# STM32H7R register map
File version: 1.3
CPU: CM7 r0p1, little endian, MPU, FPU, 4 interrupt priority bits
Registers are 32-bit, read-write, reset 0x0 unless marked. A register's access mark holds for its fields unless they carry their own. Offsets are from the block's base; [hi:lo] are bit positions; <NAME> marks a mode.

## ADF — Audio digital filter
Base 0x4002F000
0x00 GCR — ADF global control register
  [0] TRGO — Trigger output control This bit is set by software and reset by hardware. It is used to start the acquisition of several filters synchronously. It is also used to synchronize several ADF together by controlling the adf_trgo signal.
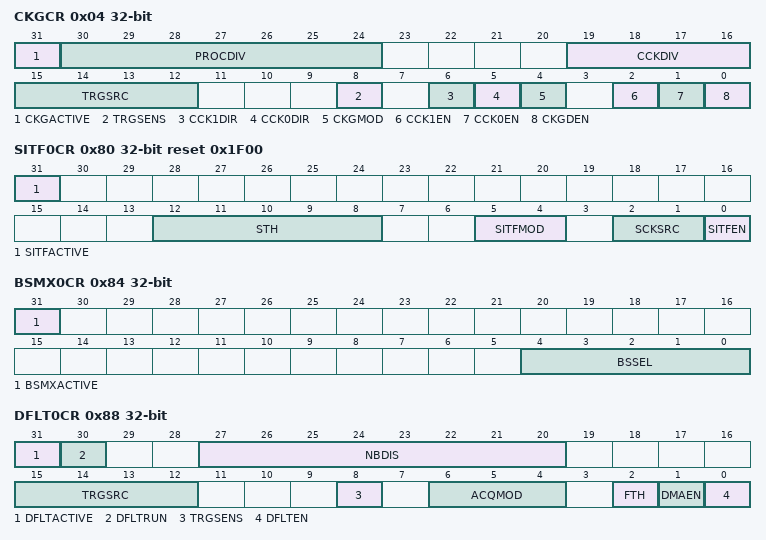
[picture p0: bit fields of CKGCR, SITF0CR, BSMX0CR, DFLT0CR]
0x04 CKGCR access per field — ADF clock generator control register
  [31] CKGACTIVE ro — Clock generator active flag This bit is set and cleared by hardware. Ii is used by the application to check if the clock generator is effectively enabled (active) or not. The protected fields of this function can only be updated when CKGACTIVE = 0 (see Section 46.4.13: Register protection for details). The delay between a transition on CKGDEN and a transition on CKGACTIVE is two periods of AHB clock and two 2 periods of adf_proc_ck.
  [30:24] PROCDIV rw — Divider to control the serial interface clock this field is set and reset by software. It is used to adjust the frequency of the clock provided to the SITF. This field must not be changed if the filter is enabled (DFTEN = 1). ... Note: This field can be write-protected (see Section 46.4.13: Register protection for details).
  [19:16] CCKDIV rw — Divider to control the ADF_CCK clock This field is set and reset by software. It is used to adjust the frequency of the ADF_CCK clock. The input clock of this divider is the clock provided to the SITF. More globally, the frequency of the ADF_CCK is given by the following formula: This field must not be changed if the filter is enabled (DFTEN = 1). ... Note: This field can be write-protected (see Section 46.4.13: Register protection for details).
  [15:12] TRGSRC rw — Digital filter trigger signal selection This field is set and cleared by software. It is used to select which external signals trigger the corresponding filter. This field is not significant if the CKGMOD = 0. 000x: TRGO selected others: reserved Note: This field can be write-protected (see Section 46.4.13: Register protection for details).
  [8] TRGSENS rw — CKGEN trigger sensitivity selection This bit is set and cleared by software. It is used to select the trigger sensitivity of the trigger signals. This bit is not significant if the CKGMOD = 0. Note: When the trigger source is TRGO, the sensitivity is forced to falling edge, thus TRGSENS value is not taken into account. This bit can be write-protected (see Section 46.4.13: Register protection for details).
  [6] CCK1DIR rw — ADF_CCK1 direction This bit is set and reset by software. It is used to control the direction of the ADF_CCK1 pin. Note: This bit can be write-protected (see Section 46.4.13: Register protection for details).
  [5] CCK0DIR rw — ADF_CCK0 direction This bit is set and reset by software. It is used to control the direction of the ADF_CCK0 pin. Note: This bit can be write-protected (see Section 46.4.13: Register protection for details).
  [4] CKGMOD rw — Clock generator mode This bit is set and reset by software. It is used to define the way the clock generator is enabled. This bit must not be changed if the filter is enabled (DFTEN = 1). Note: This bit can be write-protected (see Section 46.4.13: Register protection for details).
  [2] CCK1EN rw — ADF_CCK1 clock enable This bit is set and reset by software. It is used to control the generation of the bitstream clock on the ADF_CCK1 pin.
  [1] CCK0EN rw — ADF_CCK0 clock enable This bit is set and reset by software. It is used to control the generation of the bitstream clock on the ADF_CCK0 pin.
  [0] CKGDEN rw — CKGEN dividers enable This bit is set and reset by software. It is used to enable/disable the clock dividers of the CKGEN: PROCDIV and CCKDIV.
0x80 SITF0CR access per field reset 0x1F00 — ADF serial interface control register 0
  [31] SITFACTIVE ro — Serial interface active flag This bit is set and cleared by hardware. It is used by the application to check if the serial interface is effectively enabled (active) or not. The protected fields of this function can only be updated when SITFACTIVE is set to 0 (see Section 46.4.13: Register protection for details). The delay between a transition on SITFEN and a transition on SITFACTIVE is two periods of AHB clock and two periods of adf_proc_ck.
  [12:8] STH rw — Manchester symbol threshold/SPI threshold This field is set and cleared by software. It is used for Manchester mode to define the expected symbol threshold levels (seer to Manchester mode for details on computation). In addition this field is used to define the timeout value for the clock absence detection in Normal SPI mode. STH[4:0] values lower than four are invalid. Note: This field can be write-protected (see Section 46.4.13: Register protection for details).
  [5:4] SITFMOD rw — Serial interface type This field is set and cleared by software. It is used to define the serial interface type. Note: This field can be write-protected (see Section 46.4.13: Register protection for details).
  [2:1] SCKSRC rw — Serial clock source This field is set and cleared by software. It is used to select the clock source of the serial interface. others: reserved Note: This field can be write-protected (see Section 46.4.13: Register protection for details).
  [0] SITFEN rw — Serial interface enable This bit is set and cleared by software. It is used to enable/disable the serial interface.
0x84 BSMX0CR access per field — ADF bitstream matrix control register 0
  [31] BSMXACTIVE ro — BSMX active flag This bit is set and cleared by hardware. It is used by the application to check if the BSMX is effectively enabled (active) or not. BSSEL[4:0] can only be updated when BSMXACTIVE is set to 0. This BSMXACTIVE flag cannot go to 0 if DFLT0 is enabled.
  [4:0] BSSEL rw — Bitstream selection This field is set and cleared by software. It is used to select the bitstream to be processed for DFLT0. others: reserved Note: This field can be write-protected (see Section 46.4.13: Register protection for details).
0x88 DFLT0CR access per field — ADF digital filter control register 0
  [31] DFLTACTIVE ro — DFLT0 active flag This bit is set and cleared by hardware. It indicates if DFLT0 is active: can be running or waiting for events.
  [30] DFLTRUN ro — DFLT0 run status flag This bit is set and cleared by hardware. It indicates if DFLT0 is running or not.
  [27:20] NBDIS rw — Number of samples to be discarded This field is set and cleared by software. It is used to define the number of samples to be discarded every time DFLT0 is re-started. ... Note: This field can be write-protected (see Section 46.4.13: Register protection for details).
  [15:12] TRGSRC rw — DFLT0 trigger signal selection This field is set and cleared by software. It is used to select which external signals trigger DFLT0. others: Reserved Note: This field can be write-protected (see Section 46.4.13: Register protection for details).
  [8] TRGSENS rw — DFLT0 trigger sensitivity selection This field is set and cleared by software. It is used to select the trigger sensitivity of the external signals When the trigger source is TRGO, TRGSENS value is not taken into account. When TRGO is selected, the sensitivity is forced to falling edge. Note: This bit can be write-protected (see Section 46.4.13: Register protection for details).
  [6:4] ACQMOD rw — DFLT0 trigger mode This field is set and cleared by software. It is used to select the filter trigger mode. others: same as 000 Note: This field can be write-protected (see Section 46.4.13: Register protection for details)..
  [2] FTH rw — RXFIFO threshold selection This bit is set and cleared by software. It is used to select the RXFIFO threshold. Note: This bit can be write-protected (see Section 46.4.13: Register protection for details).
  [1] DMAEN rw — DMA requests enable This bit is set and cleared by software. It is used to control the generation of DMA request to transfer the processed samples into the memory. Note: This bit can be write-protected (see Section 46.4.13: Register protection for details).
  [0] DFLTEN wo — DFLT0 enable This bit is set and cleared by software. It is used to control the start of acquisition of the DFLT0 path. This bit behavior depends on ACQMOD[2:0] and external events. The serial or parallel interface delivering the samples must be enabled as well.
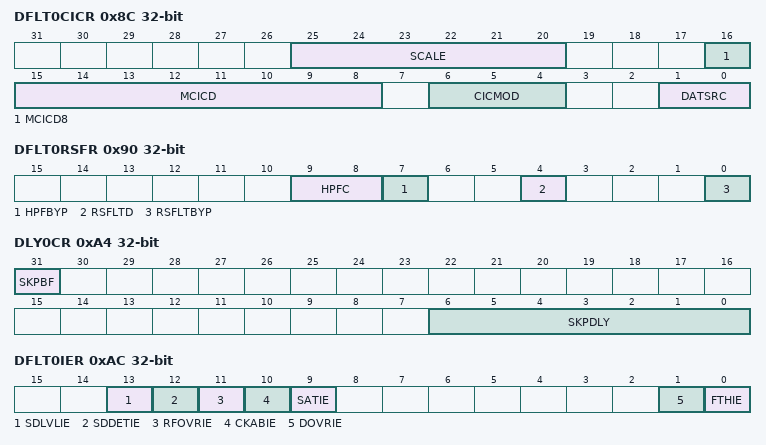
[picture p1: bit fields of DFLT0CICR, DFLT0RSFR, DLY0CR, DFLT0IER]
0x8C DFLT0CICR — ADF digital filer configuration register 0
  [25:20] SCALE — Scaling factor selection This field is set and cleared by software. It is used to select the gain to be applied at CIC output (see Table 419 for details). If the application attempts to write a new gain value while the previous one is not yet applied, this new gain value is ignored. Reading back this field informs the application on the current gain value. ... ... others: Reserved
  [16] MCICD8 — CIC decimation ratio selection This field is set and cleared by software.It is used to select the CIC decimation ratio. A decimation ratio smaller than two is not allowed. The decimation ratio is given by (CICDEC+1). ... Note: This field can be write-protected (see Section 46.4.13: Register protection for details).
  [15:8] MCICD — CIC decimation ratio selection This field is set and cleared by software.It is used to select the CIC decimation ratio. A decimation ratio smaller than two is not allowed. The decimation ratio is given by (CICDEC+1). ... Note: This field can be write-protected (see Section 46.4.13: Register protection for details).
  [6:4] CICMOD — Select the CIC order This field is set and cleared by software. It is used to select the order of the MCIC. others: reserved Note: This field can be write-protected (see Section 46.4.13: Register protection for details).
  [1:0] DATSRC — Source data for the digital filter This field is set and cleared by software. 0x: Stream coming from the BSMX selected Note: This field can be write-protected (see Section 46.4.13: Register protection for details).
0x90 DFLT0RSFR — ADF reshape filter configuration register 0
  [9:8] HPFC — High-pass filter cut-off frequency This field is set and cleared by software. it is used to select the cut-off frequency of the high-pass filter. F<sub>PCM</sub> represents the sampling frequency at HPF input. Note: This field can be write-protected (see Section 46.4.13: Register protection for details).
  [7] HPFBYP — High-pass filter bypass This bit is set and cleared by software. It is used to bypass the high-pass filter. Note: This bit can be write-protected (see Section 46.4.13: Register protection for details).
  [4] RSFLTD — Reshaper filter decimation ratio This bit is set and cleared by software. It is used to select the decimation ratio for the reshape filter Note: This bit can be write-protected (see Section 46.4.13: Register protection for details).
  [0] RSFLTBYP — Reshaper filter bypass This bit is set and cleared by software. It is used to bypass the reshape filter and its decimation block. Note: This bit can be write-protected (see Section 46.4.13: Register protection for details).
0xA4 DLY0CR access per field — ADF delay control register 0
  [31] SKPBF ro — Skip busy flag This bit is set and cleared by hardware. It is used to control if the delay sequence is completed.
  [6:0] SKPDLY rw — Delay to apply to a bitstream This field is set and cleared by software. It defines the number of input samples that are skipped. Skipping is applied immediately after writing to this field, if SKPBF = 0 and DFLTEN = 1. If SKPBF = 1, the value written into the register is ignored by the delay state machine. ...
0xAC DFLT0IER — ADF DFLT0 interrupt enable register
  [13] SDLVLIE — SAD sound-level value ready enable This bit is set and cleared by software.
  [12] SDDETIE — Sound activity detection interrupt enable This bit is set and cleared by software.
  [11] RFOVRIE — Reshape filter overrun interrupt enable This bit is set and cleared by software.
  [10] CKABIE — Clock absence detection interrupt enable This bit is set and cleared by software.
  [9] SATIE — Saturation detection interrupt enable This bit is set and cleared by software.
  [1] DOVRIE — Data overflow interrupt enable This bit is set and cleared by software.
  [0] FTHIE — RXFIFO threshold interrupt enable This bit is set and cleared by software.
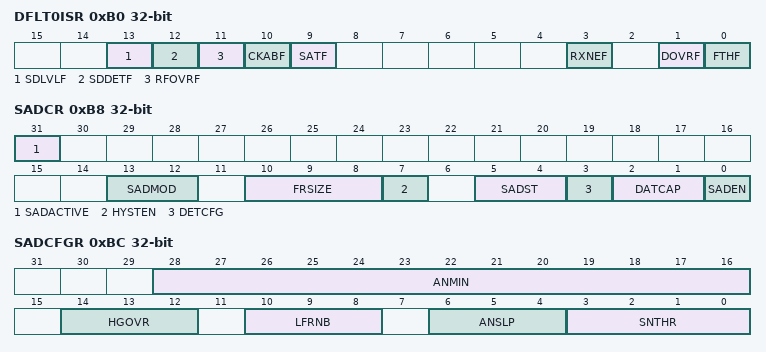
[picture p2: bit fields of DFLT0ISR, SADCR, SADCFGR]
0xB0 DFLT0ISR access per field — ADF DFLT0 interrupt status register 0
  [13] SDLVLF rw — Sound level value ready flag This bit is set by hardware and cleared by software by writing this bit to 1.
  [12] SDDETF rw — Sound activity detection flag This bit is set by hardware and cleared by software by writing this bit to 1.
  [11] RFOVRF rw — Reshape filter overrun detection flag This bit is set by hardware and cleared by software by writing this bit to 1.
  [10] CKABF rw — Clock absence detection flag This bit is set by hardware and cleared by software by writing this bit to 1.
  [9] SATF rw — Saturation detection flag This bit is set by hardware and cleared by software by writing this bit to 1.
  [3] RXNEF ro — RXFIFO not empty flag This bit is set and cleared by hardware according to the RXFIFO level.
  [1] DOVRF rw — Data overflow flag This bit is set by hardware and cleared by software by writing this bit to 1.
  [0] FTHF ro — RXFIFO threshold flag This bit is set by hardware, and cleared by the hardware when the RXFIFO level is lower than the threshold.
0xB8 SADCR access per field — ADF SAD control register
  [31] SADACTIVE ro — SAD Active flag This bit is set and cleared by hardware. It is used to check if the SAD is effectively enabled (active) or not. The protected fields and registers of this function can only be updated when the SADACTIVE is set to 0 (see Section 46.4.13: Register protection for details). The delay between a transition on SADEN and a transition on SADACTIVE is two periods of AHB clock and two periods of adf_proc_ck.
  [13:12] SADMOD rw — SAD working mode This field is set and cleared by software. It is used to define the way the SAD works. The SAD triggers when the sound level (SDLVL) is bigger than the defined threshold. In this mode, the SAD works like a voice activity detector. The SAD triggers when the sound level (SDLVL) is bigger than the defined threshold. In this mode, the SAD works like a sound detector. 1x: Threshold value given by 4 x ANMIN[12:0] The SAD triggers when the estimated ambient noise (ANLVL), multiplied by the gain selected by SNTHR[3:0] is bigger than the defined threshold. In this mode, the SAD is working like an ambient noise estimator. Hysteresis function cannot be used in this mode. Note: This field can be write-protected (see Section 46.4.13: Register protection for details).
  [10:8] FRSIZE rw — Frame size This field is set and cleared by software. it is used to define the size of one frame and also to define how many samples are taken into account to compute the short-term signal level. 11x: 512 PCM samples used to compute the short-term signal level Note: This field can be write-protected (see Section 46.4.13: Register protection for details).
  [7] HYSTEN rw — Hysteresis enable This bit is set and cleared by software. It is used to enable/disable the hysteresis function (see Table 419 for details). This bit must be kept to 0 when SADMOD[1:0] = 1x. Note: This bit can be write-protected (see Section 46.4.13: Register protection for details).
  [5:4] SADST ro — SAD state This field is set and cleared by hardware. It indicates the SAD state and is meaningful only when SADEN = 1. The SAD state can be: - LEARN when the SAD is in learning phase or in SDLVL computation mode - MONITOR when the SAD is in monitoring phase - DETECT when the SAD detects a sound
  [3] DETCFG rw — Sound trigger event configuration This bit is set and cleared by software. It is used to define if the sddet_evt event is generated only when the SAD enters to MONITOR state or when the SAD enters or exits the DETECT state. Note: This bit can be write-protected (see Section 46.4.13: Register protection for details).
  [2:1] DATCAP rw — Data capture mode This field is set and cleared by software. It is used to define in which conditions, the samples provided by DLFT0 are stored into the memory. 1x: Samples from DFLT0 transfered into memory when SAD and DFLT0 are enabled Note: This field can be write-protected (see Section 46.4.13: Register protection for details).
  [0] SADEN rw — Sound activity detector enable This bit is set and cleared by software. It is used to enable/disable the SAD.
0xBC SADCFGR — ADF SAD configuration register
  [28:16] ANMIN — Minimum noise level This field is set and cleared by software. It is used to define the minimum noise level and then the sensitivity. It represents a positive number. Note: This field can be write-protected (see Section 46.4.13: Register protection for details).
  [14:12] HGOVR — Hangover time window This field is set and cleared by software. Once the SAD state is DETECT, this parameter is used to define the amount of time the sound is allowed to remain below the threshold, before switching the SAD to MONITOR state (see FRSIZE field for the description of a frame). Note: This field can be write-protected (see Section 46.4.13: Register protection for details).
  [10:8] LFRNB — Number of learning frames This field is set and cleared by software. It is used to define the number of learning frames to perform the first estimate of the noise level. 1xx: 32 frames used to compute the initial noise level Note: This field can be write-protected (see Section 46.4.13: Register protection for details).
  [6:4] ANSLP — Ambient noise slope control This field is set and cleared by software. It is used to define the positive and negative slope of the noise estimator, in charge of updating the ANLVL (see Ambient noise estimation (ANLVL) for information about programming this field). Note: This field can be write-protected (see Section 46.4.13: Register protection for details).
  [3:0] SNTHR — Signal to noise threshold This field is set and cleared by software. It is used to define THR<sub>H </sub>(and THR<sub>L</sub> if hysteresis is enabled). See Table 419 for details. others: Reserved Note: This field can be write-protected (see Section 46.4.13: Register protection for details).
0xC0 SADSDLVR ro — ADF SAD sound level register
  [14:0] SDLVL — Short term sound level This field is set by hardware. It contains the latest sound level computed by the SAD. To refresh this value, SDLVLF must be cleared.
0xC4 SADANLVR ro — ADF SAD ambient noise level register
  [14:0] ANLVL — Ambient noise level estimation This field is set by hardware. It contains the latest ambient noise level computed by the SAD. To refresh this field, the SDLVLF flag must be cleared.
0xF0 DFLT0DR ro — ADF digital filter data register 0
  [31:8] DR — Data processed by DFT0
